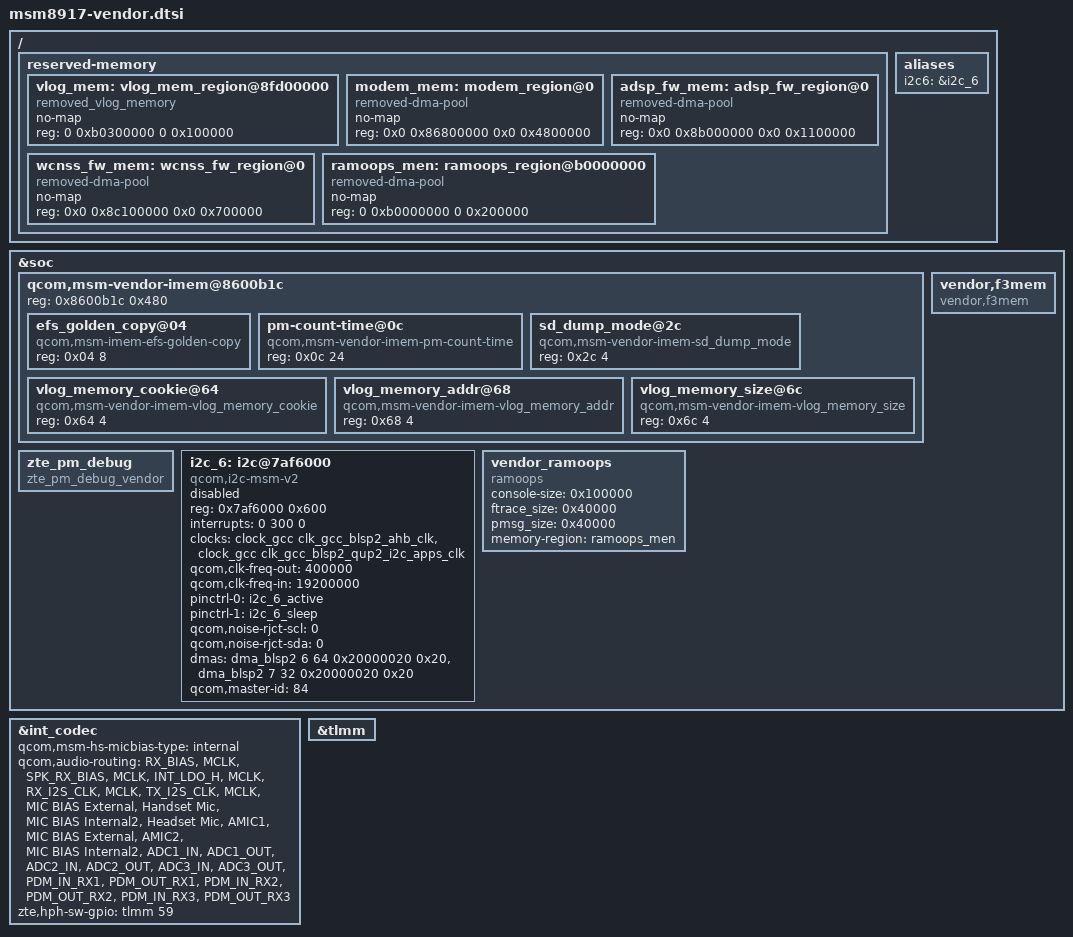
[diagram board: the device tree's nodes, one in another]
/* Copyright (c) 2014-2017, The Linux Foundation. All rights reserved.
 *
 * This program is free software; you can redistribute it and/or modify
 * it under the terms of the GNU General Public License version 2 and
 * only version 2 as published by the Free Software Foundation.
 *
 * This program is distributed in the hope that it will be useful,
 * but WITHOUT ANY WARRANTY; without even the implied warranty of
 * MERCHANTABILITY or FITNESS FOR A PARTICULAR PURPOSE.  See the
 * GNU General Public License for more details.
 */


/ {
	  reserved-memory {
		#address-cells = <2>;
		#size-cells = <2>;
		vlog_mem:vlog_mem_region@8fd00000 {
			compatible = "removed_vlog_memory";
			no-map;
			reg = <0 0xb0300000 0 0x100000>;
		};

		modem_mem: modem_region@0 {
			compatible = "removed-dma-pool";
			no-map;
			reg = <0x0 0x86800000 0x0 0x4800000>;
		};

		adsp_fw_mem: adsp_fw_region@0 {
			compatible = "removed-dma-pool";
			no-map;
			reg = <0x0 0x8b000000 0x0 0x1100000>;
		};

		wcnss_fw_mem: wcnss_fw_region@0 {
			compatible = "removed-dma-pool";
			no-map;
			reg = <0x0 0x8c100000 0x0 0x700000>;
		};

		/*add by ZTE_BOOT*/
		ramoops_men: ramoops_region@b0000000 {
			compatible = "removed-dma-pool";
			no-map;
			reg = <0 0xb0000000 0 0x200000>;
		};
	};

	aliases {
		i2c6 = &i2c_6;
	};
};

&soc {
	/delete-node/ msm_cdc_pinctrl_quin;

	qcom,msm-vendor-imem@8600b1c {
		reg = <0x8600b1c 0x480>; /* Address and size of IMEM */
		ranges = <0x0 0x8600b1c 0x480>;
		#address-cells = <1>;
		#size-cells = <1>;
		efs_golden_copy@04 {
			compatible = "qcom,msm-imem-efs-golden-copy";
			reg = <0x04 8>;
		};

		pm-count-time@0c {
			compatible = "qcom,msm-vendor-imem-pm-count-time";
			reg = <0x0c 24>;
		};

		sd_dump_mode@2c {
			compatible = "qcom,msm-vendor-imem-sd_dump_mode";
			reg = <0x2c 4>;
		};

		vlog_memory_cookie@64 {
			compatible = "qcom,msm-vendor-imem-vlog_memory_cookie";
			reg = <0x64 4>;
		};

		vlog_memory_addr@68 {
			compatible = "qcom,msm-vendor-imem-vlog_memory_addr";
			reg = <0x68 4>;
		};

		vlog_memory_size@6c {
			compatible = "qcom,msm-vendor-imem-vlog_memory_size";
			reg = <0x6c 4>;
		};
	};

	vendor,f3mem{
		compatible = "vendor,f3mem";
	};
	zte_pm_debug {
		compatible = "zte_pm_debug_vendor";
	};

	i2c_6: i2c@7af6000 { /* BLSP2 QUP2 */
		compatible = "qcom,i2c-msm-v2";
		#address-cells = <1>;
		#size-cells = <0>;
		reg-names = "qup_phys_addr";
		reg = <0x7af6000 0x600>;
		interrupt-names = "qup_irq";
		interrupts = <0 300 0>;
		clock-names = "iface_clk", "core_clk";
		clocks = <&clock_gcc clk_gcc_blsp2_ahb_clk>,
			 <&clock_gcc clk_gcc_blsp2_qup2_i2c_apps_clk>;
		qcom,clk-freq-out = <400000>;
		qcom,clk-freq-in  = <19200000>;
		pinctrl-names = "i2c_active", "i2c_sleep";
		pinctrl-0 = <&i2c_6_active>;
		pinctrl-1 = <&i2c_6_sleep>;
		qcom,noise-rjct-scl = <0>;
		qcom,noise-rjct-sda = <0>;
		dmas = <&dma_blsp2 6 64 0x20000020 0x20>,
		<&dma_blsp2 7 32 0x20000020 0x20>;
		dma-names = "tx", "rx";
		qcom,master-id = <84>;
		status = "disabled";
	};

	vendor_ramoops{
		compatible = "ramoops";
		console-size = <0x100000>;
		ftrace_size = <0x40000>;
		pmsg_size = <0x40000>;
		memory-region = <&ramoops_men>;
	};
};

&int_codec {
	/delete-property/ qcom,quin-mi2s-gpios;

	qcom,msm-hs-micbias-type = "internal";
	qcom,audio-routing =
			"RX_BIAS", "MCLK",
			"SPK_RX_BIAS", "MCLK",
			"INT_LDO_H", "MCLK",
			"RX_I2S_CLK", "MCLK",
			"TX_I2S_CLK", "MCLK",
			"MIC BIAS External", "Handset Mic",
			"MIC BIAS Internal2", "Headset Mic",
			"AMIC1", "MIC BIAS External",
			"AMIC2", "MIC BIAS Internal2",
			"ADC1_IN", "ADC1_OUT",
			"ADC2_IN", "ADC2_OUT",
			"ADC3_IN", "ADC3_OUT",
			"PDM_IN_RX1", "PDM_OUT_RX1",
			"PDM_IN_RX2", "PDM_OUT_RX2",
			"PDM_IN_RX3", "PDM_OUT_RX3";
	zte,hph-sw-gpio = <&tlmm 59 0x0>;
};

&tlmm {
	/delete-node/ pri-tlmm-lines;
	/delete-node/ pri-tlmm-ws-lines;
};
